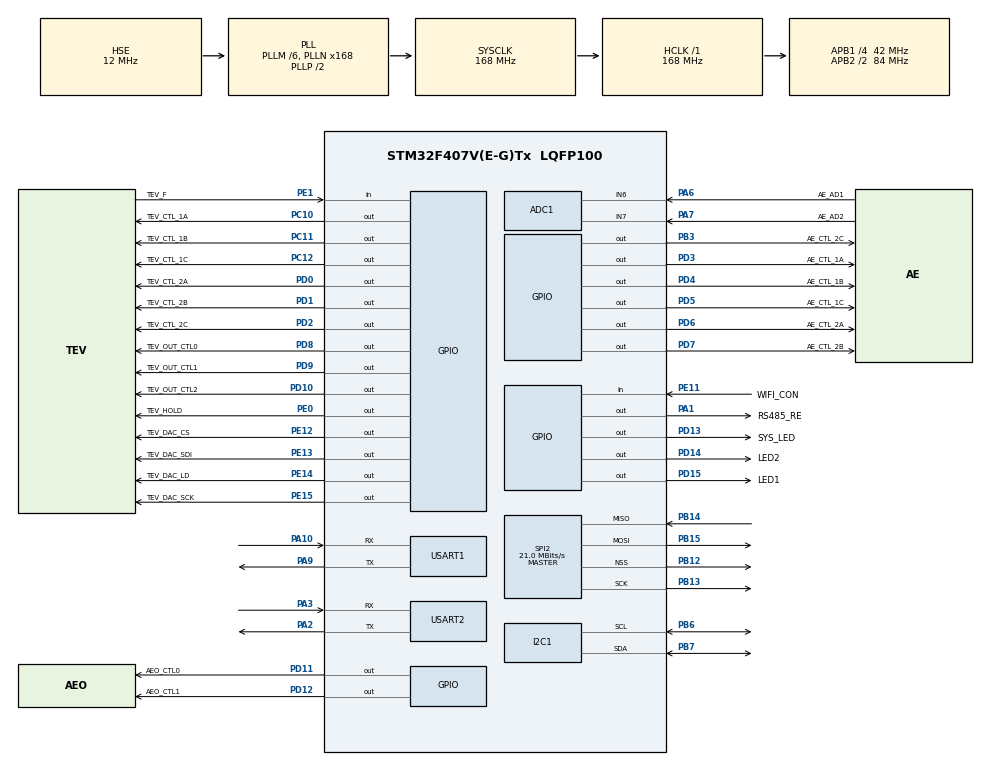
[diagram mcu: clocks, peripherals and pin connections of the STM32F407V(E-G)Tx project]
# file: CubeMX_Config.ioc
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ADC1.Channel-0\#ChannelRegularConversion=ADC_CHANNEL_6
ADC1.NbrOfConversionFlag=1
ADC1.Rank-0\#ChannelRegularConversion=1
ADC1.SamplingTime-0\#ChannelRegularConversion=ADC_SAMPLETIME_3CYCLES
ADC1.master=1
Dma.Request0=USART1_TX
Dma.Request1=USART1_RX
Dma.Request2=USART2_RX
Dma.Request3=USART2_TX
Dma.USART1_RX.1.Direction=DMA_PERIPH_TO_MEMORY
Dma.USART1_RX.1.FIFOMode=DMA_FIFOMODE_DISABLE
Dma.USART1_RX.1.Instance=DMA2_Stream2
Dma.USART1_RX.1.MemDataAlignment=DMA_MDATAALIGN_BYTE
Dma.USART1_RX.1.MemInc=DMA_MINC_ENABLE
Dma.USART1_RX.1.Mode=DMA_NORMAL
Dma.USART1_RX.1.PeriphDataAlignment=DMA_PDATAALIGN_BYTE
Dma.USART1_RX.1.PeriphInc=DMA_PINC_DISABLE
Dma.USART1_RX.1.Priority=DMA_PRIORITY_LOW
Dma.USART1_TX.0.Direction=DMA_MEMORY_TO_PERIPH
Dma.USART1_TX.0.FIFOMode=DMA_FIFOMODE_DISABLE
Dma.USART1_TX.0.Instance=DMA2_Stream7
Dma.USART1_TX.0.MemDataAlignment=DMA_MDATAALIGN_BYTE
Dma.USART1_TX.0.MemInc=DMA_MINC_ENABLE
Dma.USART1_TX.0.Mode=DMA_NORMAL
Dma.USART1_TX.0.PeriphDataAlignment=DMA_PDATAALIGN_BYTE
Dma.USART1_TX.0.PeriphInc=DMA_PINC_DISABLE
Dma.USART1_TX.0.Priority=DMA_PRIORITY_LOW
Dma.USART2_RX.2.Direction=DMA_PERIPH_TO_MEMORY
Dma.USART2_RX.2.FIFOMode=DMA_FIFOMODE_DISABLE
Dma.USART2_RX.2.Instance=DMA1_Stream5
Dma.USART2_RX.2.MemDataAlignment=DMA_MDATAALIGN_BYTE
Dma.USART2_RX.2.MemInc=DMA_MINC_ENABLE
Dma.USART2_RX.2.Mode=DMA_NORMAL
Dma.USART2_RX.2.PeriphDataAlignment=DMA_PDATAALIGN_BYTE
Dma.USART2_RX.2.PeriphInc=DMA_PINC_DISABLE
Dma.USART2_RX.2.Priority=DMA_PRIORITY_LOW
Dma.USART2_TX.3.Direction=DMA_MEMORY_TO_PERIPH
Dma.USART2_TX.3.FIFOMode=DMA_FIFOMODE_DISABLE
Dma.USART2_TX.3.Instance=DMA1_Stream6
Dma.USART2_TX.3.MemDataAlignment=DMA_MDATAALIGN_BYTE
Dma.USART2_TX.3.MemInc=DMA_MINC_ENABLE
Dma.USART2_TX.3.Mode=DMA_NORMAL
Dma.USART2_TX.3.PeriphDataAlignment=DMA_PDATAALIGN_BYTE
Dma.USART2_TX.3.PeriphInc=DMA_PINC_DISABLE
Dma.USART2_TX.3.Priority=DMA_PRIORITY_LOW
Mcu.Family=STM32F4
Mcu.Name=STM32F407V(E-G)Tx
Mcu.Package=LQFP100
NVIC.DMA1_Stream5_IRQn=true\:0\:0\:false\:false\:true\:false\:true
NVIC.DMA1_Stream6_IRQn=true\:0\:0\:false\:false\:true\:false\:true
NVIC.DMA2_Stream2_IRQn=true\:0\:0\:false\:false\:true\:false\:true
NVIC.DMA2_Stream7_IRQn=true\:0\:0\:false\:false\:true\:false\:true
NVIC.PriorityGroup=NVIC_PRIORITYGROUP_4
NVIC.USART1_IRQn=true\:0\:0\:false\:false\:true\:true\:true
NVIC.USART2_IRQn=true\:0\:0\:false\:false\:true\:true\:true
PA1.GPIO_Label=RS485_RE
PA1.Signal=GPIO_Output
PA10.Mode=Asynchronous
PA10.Signal=USART1_RX
PA13.Mode=Serial_Wire
PA13.Signal=SYS_JTMS-SWDIO
PA14.Mode=Serial_Wire
PA14.Signal=SYS_JTCK-SWCLK
PA2.Mode=Asynchronous
PA2.Signal=USART2_TX
PA3.Mode=Asynchronous
PA3.Signal=USART2_RX
PA6.GPIO_Label=AE_AD1
PA6.Signal=ADCx_IN6
PA7.GPIO_Label=AE_AD2
PA7.Signal=ADCx_IN7
PA9.Mode=Asynchronous
PA9.Signal=USART1_TX
PB12.Mode=NSS_Signal_Hard_Output
PB12.Signal=SPI2_NSS
PB13.Mode=Full_Duplex_Master
PB13.Signal=SPI2_SCK
PB14.Mode=Full_Duplex_Master
PB14.Signal=SPI2_MISO
PB15.Mode=Full_Duplex_Master
PB15.Signal=SPI2_MOSI
PB3.GPIO_Label=AE_CTL_2C
PB3.Signal=GPIO_Output
PB6.Mode=I2C
PB6.Signal=I2C1_SCL
PB7.Mode=I2C
PB7.Signal=I2C1_SDA
PC10.GPIO_Label=TEV_CTL_1A
PC10.Signal=GPIO_Output
PC11.GPIO_Label=TEV_CTL_1B
PC11.Signal=GPIO_Output
PC12.GPIO_Label=TEV_CTL_1C
PC12.Signal=GPIO_Output
PD0.GPIO_Label=TEV_CTL_2A
PD0.Signal=GPIO_Output
PD1.GPIO_Label=TEV_CTL_2B
PD1.Signal=GPIO_Output
PD10.GPIO_Label=TEV_OUT_CTL2
PD10.Signal=GPIO_Output
PD11.GPIO_Label=AEO_CTL0
PD11.Signal=GPIO_Output
PD12.GPIO_Label=AEO_CTL1
PD12.Signal=GPIO_Output
PD13.GPIO_Label=SYS_LED
PD13.Signal=GPIO_Output
PD14.GPIO_Label=LED2
PD14.Signal=GPIO_Output
PD15.GPIO_Label=LED1
PD15.Signal=GPIO_Output
PD2.GPIO_Label=TEV_CTL_2C
PD2.Signal=GPIO_Output
PD3.GPIO_Label=AE_CTL_1A
PD3.Signal=GPIO_Output
PD4.GPIO_Label=AE_CTL_1B
PD4.Signal=GPIO_Output
PD5.GPIO_Label=AE_CTL_1C
PD5.Signal=GPIO_Output
PD6.GPIO_Label=AE_CTL_2A
PD6.Signal=GPIO_Output
PD7.GPIO_Label=AE_CTL_2B
PD7.Signal=GPIO_Output
PD8.GPIO_Label=TEV_OUT_CTL0
PD8.Signal=GPIO_Output
PD9.GPIO_Label=TEV_OUT_CTL1
PD9.Signal=GPIO_Output
PE0.GPIO_Label=TEV_HOLD
PE0.Signal=GPIO_Output
PE1.GPIO_Label=TEV_F
PE1.Signal=GPIO_Input
PE11.GPIO_Label=WIFI_CON
PE11.Signal=GPIO_Input
PE12.GPIO_Label=TEV_DAC_CS
PE12.Signal=GPIO_Output
PE13.GPIO_Label=TEV_DAC_SDI
PE13.Signal=GPIO_Output
PE14.GPIO_Label=TEV_DAC_LD
PE14.Signal=GPIO_Output
PE15.GPIO_Label=TEV_DAC_SCK
PE15.Signal=GPIO_Output
PH0-OSC_IN.Mode=HSE-External-Oscillator
PH0-OSC_IN.Signal=RCC_OSC_IN
PH1-OSC_OUT.Mode=HSE-External-Oscillator
PH1-OSC_OUT.Signal=RCC_OSC_OUT
ProjectManager.HeapSize=0x200
ProjectManager.StackSize=0x400
ProjectManager.TargetToolchain=MDK-ARM V5
RCC.48MHZClocksFreq_Value=84000000
RCC.AHBFreq_Value=168000000
RCC.APB1CLKDivider=RCC_HCLK_DIV4
RCC.APB1Freq_Value=42000000
RCC.APB1TimFreq_Value=84000000
RCC.APB2CLKDivider=RCC_HCLK_DIV2
RCC.APB2Freq_Value=84000000
RCC.APB2TimFreq_Value=168000000
RCC.CortexFreq_Value=168000000
RCC.HCLKFreq_Value=168000000
RCC.HSE_VALUE=12000000
RCC.HSI_VALUE=16000000
RCC.LSE_VALUE=32768
RCC.PLLM=6
RCC.PLLN=168
RCC.PLLSourceVirtual=RCC_PLLSOURCE_HSE
RCC.SYSCLKFreq_VALUE=168000000
RCC.SYSCLKSource=RCC_SYSCLKSOURCE_PLLCLK
RCC.VCOOutputFreq_Value=336000000
SH.ADCx_IN6.0=ADC1_IN6,IN6
SH.ADCx_IN7.0=ADC1_IN7,IN7
SPI2.CalculateBaudRate=21.0 MBits/s
SPI2.Direction=SPI_DIRECTION_2LINES
SPI2.Mode=SPI_MODE_MASTER
SPI2.VirtualNSS=VM_NSSHARD
SPI2.VirtualType=VM_MASTER
USART1.VirtualMode=VM_ASYNC
USART2.VirtualMode=VM_ASYNC
board=custom

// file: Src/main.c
/* USER CODE BEGIN Header */
/**
  ******************************************************************************
  * @file           : main.c
  * @brief          : Main program body
  ******************************************************************************
  * @attention
  *
  * <h2><center>&copy; Copyright (c) 2019 STMicroelectronics.
  * All rights reserved.</center></h2>
  *
  * This software component is licensed by ST under BSD 3-Clause license,
  * the "License"; You may not use this file except in compliance with the
  * License. You may obtain a copy of the License at:
  *                        opensource.org/licenses/BSD-3-Clause
  *
  ******************************************************************************
  */
/* USER CODE END Header */

#include "main.h"
#include "adc.h"
#include "dma.h"
#include "i2c.h"
#include "spi.h"
#include "usart.h"
#include "gpio.h"

void SystemClock_Config(void);

int main(void)
{

  /* MCU Configuration--------------------------------------------------------*/

  /* Reset of all peripherals, Initializes the Flash interface and the Systick. */
  HAL_Init();

  /* Configure the system clock */
  SystemClock_Config();

  /* Initialize all configured peripherals */
  MX_GPIO_Init();
  MX_DMA_Init();
  MX_USART1_UART_Init();
  MX_I2C1_Init();
  MX_ADC1_Init();
  MX_USART2_UART_Init();
  MX_SPI2_Init();
  /* USER CODE BEGIN 2 */

 HAL_UART_Transmit(&huart1, "123",3,55);
  /* USER CODE END 2 */

  /* Infinite loop */
  while (1)
  {

  }
}

void SystemClock_Config(void)
{
  RCC_OscInitTypeDef RCC_OscInitStruct = {0};
  RCC_ClkInitTypeDef RCC_ClkInitStruct = {0};

  /** Configure the main internal regulator output voltage
  */
  __HAL_RCC_PWR_CLK_ENABLE();
  __HAL_PWR_VOLTAGESCALING_CONFIG(PWR_REGULATOR_VOLTAGE_SCALE1);
  /** Initializes the CPU, AHB and APB busses clocks
  */
  RCC_OscInitStruct.OscillatorType = RCC_OSCILLATORTYPE_HSE;
  RCC_OscInitStruct.HSEState = RCC_HSE_ON;
  RCC_OscInitStruct.PLL.PLLState = RCC_PLL_ON;
  RCC_OscInitStruct.PLL.PLLSource = RCC_PLLSOURCE_HSE;
  RCC_OscInitStruct.PLL.PLLM = 6;
  RCC_OscInitStruct.PLL.PLLN = 168;
  RCC_OscInitStruct.PLL.PLLP = RCC_PLLP_DIV2;
  RCC_OscInitStruct.PLL.PLLQ = 4;
  if (HAL_RCC_OscConfig(&RCC_OscInitStruct) != HAL_OK)
  {
    Error_Handler();
  }
  /** Initializes the CPU, AHB and APB busses clocks
  */
  RCC_ClkInitStruct.ClockType = RCC_CLOCKTYPE_HCLK|RCC_CLOCKTYPE_SYSCLK
                              |RCC_CLOCKTYPE_PCLK1|RCC_CLOCKTYPE_PCLK2;
  RCC_ClkInitStruct.SYSCLKSource = RCC_SYSCLKSOURCE_PLLCLK;
  RCC_ClkInitStruct.AHBCLKDivider = RCC_SYSCLK_DIV1;
  RCC_ClkInitStruct.APB1CLKDivider = RCC_HCLK_DIV4;
  RCC_ClkInitStruct.APB2CLKDivider = RCC_HCLK_DIV2;

  if (HAL_RCC_ClockConfig(&RCC_ClkInitStruct, FLASH_LATENCY_5) != HAL_OK)
  {
    Error_Handler();
  }
}

void Error_Handler(void)
{
}

/************************ (C) COPYRIGHT STMicroelectronics *****END OF FILE****/
